# ENUMDEF32 register map
File version: 1.0
E05 tested: field with isDefault entry (explicit value) and field without default
Registers are 32-bit, access not given, no defined reset value unless marked. A register's access mark holds for its fields unless they carry their own. Offsets are from the block's base; lines under a group give offsets from that group; [hi:lo] are bit positions; {n}, {i} and the like mark numbered series; 'fields as' and 'values as' point back to an identical list; <NAME> marks a mode.

## Memory map
0x40000000 MOD

## MOD
Base 0x40000000
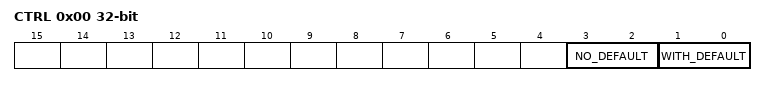
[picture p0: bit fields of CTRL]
0x00 CTRL
  [3:2] NO_DEFAULT — Only two explicit values, no default
    0=A; 1=B
  [1:0] WITH_DEFAULT — Two explicit values plus a default entry carrying an explicit value
    0=A; 1=B; 0=OTHER
